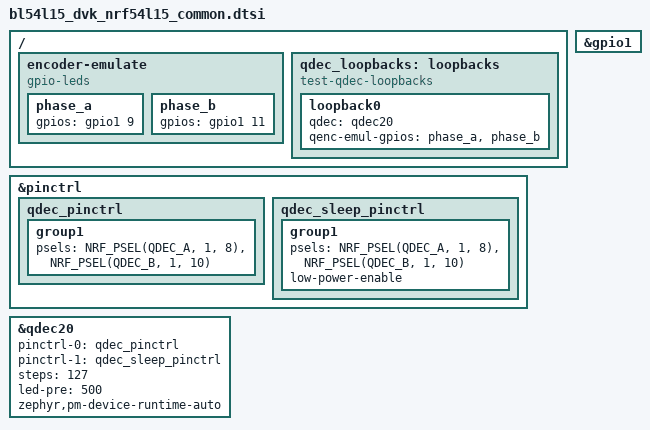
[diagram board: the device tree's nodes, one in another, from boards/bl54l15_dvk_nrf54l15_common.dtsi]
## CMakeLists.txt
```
# SPDX-License-Identifier: Apache-2.0

cmake_minimum_required(VERSION 3.28.0)

find_package(Zephyr REQUIRED HINTS $ENV{ZEPHYR_BASE})
project(qdec_sensor)

FILE(GLOB app_sources src/*.c)

target_sources(app PRIVATE ${app_sources})
```

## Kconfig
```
# Copyright (c) 2025 Nordic Semiconductor ASA
# SPDX-License-Identifier: Apache-2.0

config SECOND_QDEC_INSTANCE
	bool "Enable second !DEC instance"

source "Kconfig.zephyr"
```

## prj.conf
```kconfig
CONFIG_ZTEST=y
CONFIG_SENSOR=y
CONFIG_SENSOR_ASYNC_API=y
CONFIG_GPIO=y
CONFIG_RTIO=y
```

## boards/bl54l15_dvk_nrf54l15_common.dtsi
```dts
/*
 * Copyright 2024 Nordic Semiconductor ASA
 * Copyright 2025 Ezurio LLC
 * SPDX-License-Identifier: Apache-2.0
 */

/ {
	encoder-emulate {
		compatible = "gpio-leds";

		phase_a: phase_a {
			gpios = <&gpio1 9 GPIO_ACTIVE_HIGH>;
		};

		phase_b: phase_b {
			gpios = <&gpio1 11 GPIO_ACTIVE_HIGH>;
		};
	};

	qdec_loopbacks: loopbacks {
		compatible = "test-qdec-loopbacks";

		loopback0 {
			qdec = <&qdec20>;
			qenc-emul-gpios = <&phase_a &phase_b>;
		};
	};
};

&pinctrl {
	qdec_pinctrl: qdec_pinctrl {
		group1 {
			psels = <NRF_PSEL(QDEC_A, 1, 8)>,
				<NRF_PSEL(QDEC_B, 1, 10)>;
		};
	};

	qdec_sleep_pinctrl: qdec_sleep_pinctrl {
		group1 {
			psels = <NRF_PSEL(QDEC_A, 1, 8)>,
				<NRF_PSEL(QDEC_B, 1, 10)>;
			low-power-enable;
		};
	};
};

&gpio1 {
	status = "okay";
};

&qdec20 {
	pinctrl-0 = <&qdec_pinctrl>;
	pinctrl-1 = <&qdec_sleep_pinctrl>;
	pinctrl-names = "default", "sleep";
	steps = <127>;
	led-pre = <500>;
	zephyr,pm-device-runtime-auto;
	status = "okay";
};
```

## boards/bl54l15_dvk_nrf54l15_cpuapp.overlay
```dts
/*
 * Copyright 2024 Nordic Semiconductor ASA
 * Copyright 2025 Ezurio LLC
 * SPDX-License-Identifier: Apache-2.0
 */

#include "bl54l15_dvk_nrf54l15_common.dtsi"

/* To prevent enabling console receiver. */
&uart20 {
	disable-rx;
};
```

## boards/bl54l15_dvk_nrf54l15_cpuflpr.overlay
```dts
/*
 * Copyright 2024 Nordic Semiconductor ASA
 * Copyright 2025 Ezurio LLC
 * SPDX-License-Identifier: Apache-2.0
 */

#include "bl54l15_dvk_nrf54l15_common.dtsi"

/* To prevent enabling console receiver. */
&uart30 {
	disable-rx;
};
```

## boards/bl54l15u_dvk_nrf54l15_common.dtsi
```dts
/*
 * Copyright 2024 Nordic Semiconductor ASA
 * Copyright 2025 Ezurio LLC
 * SPDX-License-Identifier: Apache-2.0
 */

/ {
	encoder-emulate {
		compatible = "gpio-leds";

		phase_a: phase_a {
			gpios = <&gpio1 9 GPIO_ACTIVE_HIGH>;
		};

		phase_b: phase_b {
			gpios = <&gpio1 11 GPIO_ACTIVE_HIGH>;
		};
	};

	qdec_loopbacks: loopbacks {
		compatible = "test-qdec-loopbacks";

		loopback0 {
			qdec = <&qdec20>;
			qenc-emul-gpios = <&phase_a &phase_b>;
		};
	};
};

&pinctrl {
	qdec_pinctrl: qdec_pinctrl {
		group1 {
			psels = <NRF_PSEL(QDEC_A, 1, 8)>,
				<NRF_PSEL(QDEC_B, 1, 10)>;
		};
	};

	qdec_sleep_pinctrl: qdec_sleep_pinctrl {
		group1 {
			psels = <NRF_PSEL(QDEC_A, 1, 8)>,
				<NRF_PSEL(QDEC_B, 1, 10)>;
			low-power-enable;
		};
	};
};

&gpio1 {
	status = "okay";
};

&qdec20 {
	status = "okay";
	pinctrl-0 = <&qdec_pinctrl>;
	pinctrl-1 = <&qdec_sleep_pinctrl>;
	pinctrl-names = "default", "sleep";
	steps = <127>;
	led-pre = <500>;
	zephyr,pm-device-runtime-auto;
};
```

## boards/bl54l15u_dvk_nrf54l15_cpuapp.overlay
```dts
/*
 * Copyright 2024 Nordic Semiconductor ASA
 * Copyright 2025 Ezurio LLC
 * SPDX-License-Identifier: Apache-2.0
 */

#include "bl54l15u_dvk_nrf54l15_common.dtsi"

/* To prevent enabling console receiver. */
&uart20 {
	disable-rx;
};
```

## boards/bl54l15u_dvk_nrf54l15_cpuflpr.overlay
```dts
/*
 * Copyright 2024 Nordic Semiconductor ASA
 * Copyright 2025 Ezurio LLC
 * SPDX-License-Identifier: Apache-2.0
 */

#include "bl54l15u_dvk_nrf54l15_common.dtsi"

/* To prevent enabling console receiver. */
&uart30 {
	disable-rx;
};
```

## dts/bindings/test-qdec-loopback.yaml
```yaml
description: |
  Binding describing loopbacks required to run tests/boards/nrf/qdec test in Zephyr.

compatible: "test-qdec-loopbacks"

child-binding:
  description: |
    Binding describing a single loopback pair consisting of a QDEC device and two "gpio-leds" pins
    working as a quadrature encoder for the test.
  properties:
    qdec:
      type: phandle
      required: true
      description: Node of the QDEC device used to capture quadrature signal in the loopback.
    qenc-emul-gpios:
      type: phandles
      required: true
      description: |
        Children nodes of "gpio-leds" compatible used to generate quadrature signal. The first
        phandles outputs phase A signal, the second one outputs phase B signal.
```

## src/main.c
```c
/*
 * Copyright (c) 2024, Nordic Semiconductor ASA
 *
 * SPDX-License-Identifier: Apache-2.0
 */

#include <zephyr/ztest.h>
#include <zephyr/kernel.h>
#include <zephyr/device.h>
#include <zephyr/drivers/sensor.h>
#include <zephyr/drivers/gpio.h>
#include <zephyr/pm/device_runtime.h>
#include <zephyr/rtio/rtio.h>

/**
 * Structure grouping gpio pins used for QENC emulation connected with a QDEC device
 * with a loopback.
 */
struct qdec_qenc_loopback {
	struct gpio_dt_spec qenc_phase_a;
	struct gpio_dt_spec qenc_phase_b;

	const struct device *qdec;
	uint32_t qdec_config_step;

	struct rtio_iodev *qdec_iodev;
};

static K_SEM_DEFINE(sem, 0, 1);

RTIO_DEFINE(ctx, 1, 1);

#define GET_QDEC_QENC_IODEV_DEFINE(x)                                                              \
	SENSOR_DT_READ_IODEV(iodev##x, DT_PHANDLE(x, qdec), {SENSOR_CHAN_ROTATION, 0});

DT_FOREACH_CHILD(DT_NODELABEL(qdec_loopbacks), GET_QDEC_QENC_IODEV_DEFINE)

#define GET_QDEC_QENC_LOOPBACK(x)                                                                  \
	{                                                                                          \
		.qenc_phase_a = GPIO_DT_SPEC_GET(DT_PHANDLE_BY_IDX(x, qenc_emul_gpios, 0), gpios), \
		.qenc_phase_b = GPIO_DT_SPEC_GET(DT_PHANDLE_BY_IDX(x, qenc_emul_gpios, 1), gpios), \
		.qdec = DEVICE_DT_GET(DT_PHANDLE(x, qdec)),                                        \
		.qdec_config_step = DT_PROP_BY_PHANDLE(x, qdec, steps),                            \
		.qdec_iodev = &iodev##x,                                                           \
	}

struct qdec_qenc_loopback loopbacks[] = {
	DT_FOREACH_CHILD_SEP(DT_NODELABEL(qdec_loopbacks), GET_QDEC_QENC_LOOPBACK, (,))
};

#define TESTED_QDEC_COUNT ARRAY_SIZE(loopbacks)

static struct sensor_trigger qdec_trigger = {.type = SENSOR_TRIG_DATA_READY,
					     .chan = SENSOR_CHAN_ROTATION};

static bool toggle_a = true;
static struct qdec_qenc_loopback *loopback_currently_under_test;

static void qdec_trigger_handler(const struct device *dev, const struct sensor_trigger *trigger)
{
	zassert_not_null(dev);
	zassert_not_null(trigger);
	/* trigger should be stored as a pointer in a driver
	 * thus this address should match
	 */
	zassert_equal_ptr(trigger, &qdec_trigger);

	k_sem_give(&sem);
}

static void qenc_emulate_work_handler(struct k_work *work)
{
	/* Check if emulation has been stopped after submitting this work item. */
	if (loopback_currently_under_test == NULL) {
		return;
	}

	if (toggle_a) {
		gpio_pin_toggle_dt(&loopback_currently_under_test->qenc_phase_a);
	} else {
		gpio_pin_toggle_dt(&loopback_currently_under_test->qenc_phase_b);
	}
	toggle_a = !toggle_a;
}

static K_WORK_DEFINE(qenc_emulate_work, qenc_emulate_work_handler);

static void qenc_emulate_timer_handler(struct k_timer *dummy)
{
	k_work_submit(&qenc_emulate_work);
}

static K_TIMER_DEFINE(qenc_emulate_timer, qenc_emulate_timer_handler, NULL);

static void qenc_emulate_reset_pin(const struct gpio_dt_spec *gpio_dt)
{
	int rc;

	rc = gpio_pin_set_dt(gpio_dt, 0);
	zassert_ok(rc, "%s: pin set failed: %d", gpio_dt->port->name, rc);
}

static void qenc_emulate_setup_pin(const struct gpio_dt_spec *gpio_dt)
{
	int rc;

	rc = gpio_is_ready_dt(gpio_dt);
	zassert_true(rc, "%s: device not ready: %d", gpio_dt->port->name, rc);

	rc = gpio_pin_configure_dt(gpio_dt, GPIO_OUTPUT);
	zassert_true(rc == 0, "%s: pin configure failed: %d", gpio_dt->port->name, rc);
}

static void qenc_emulate_start(struct qdec_qenc_loopback *loopback, k_timeout_t period,
		bool forward)
{
	qenc_emulate_reset_pin(&loopback->qenc_phase_a);
	qenc_emulate_reset_pin(&loopback->qenc_phase_b);

	toggle_a = !forward;
	loopback_currently_under_test = loopback;
	k_timer_start(&qenc_emulate_timer, period, period);
}

static void qenc_emulate_stop(void)
{
	if (loopback_currently_under_test) {
		k_timer_stop(&qenc_emulate_timer);
		qenc_emulate_reset_pin(&loopback_currently_under_test->qenc_phase_a);
		qenc_emulate_reset_pin(&loopback_currently_under_test->qenc_phase_b);

		loopback_currently_under_test = NULL;
	}
}

static void qenc_emulate_verify_reading(struct qdec_qenc_loopback *loopback,
		int emulator_period_ms, int emulation_duration_ms, bool forward,
		bool overflow_expected)
{
	int rc;
	struct sensor_value val = {0};
	int32_t expected_steps = emulation_duration_ms / emulator_period_ms;
	int32_t expected_reading = 360 * expected_steps / loopback->qdec_config_step;
	int32_t delta = expected_reading / 4;

	if (!forward) {
		expected_reading *= -1;
	}

	qenc_emulate_start(loopback, K_MSEC(emulator_period_ms), forward);

	/* wait for some readings */
	k_msleep(emulation_duration_ms);

	rc = sensor_sample_fetch(loopback->qdec);

	if (!overflow_expected) {
		zassert_true(rc == 0, "Failed to fetch sample (%d)", rc);
	} else {
		zassert_true(rc == -EOVERFLOW, "Failed to detect overflow");
	}

	rc = sensor_channel_get(loopback->qdec, SENSOR_CHAN_ROTATION, &val);
	zassert_true(rc == 0, "Failed to get sample (%d)", rc);

	TC_PRINT("Expected reading: %d, actual value: %d, delta: %d\n",
			expected_reading, val.val1, delta);
	if (!overflow_expected) {
		zassert_within(val.val1, expected_reading, delta,
			       "Expected reading: %d,  but got: %d", expected_reading, val.val1);
	}

	qenc_emulate_stop();

	/* wait and get readings to clear state */
	k_msleep(100);

	rc = sensor_sample_fetch(loopback->qdec);
	zassert_true(rc == 0, "Failed to fetch sample (%d)", rc);

	rc = sensor_channel_get(loopback->qdec, SENSOR_CHAN_ROTATION, &val);
	zassert_true(rc == 0, "Failed to get sample (%d)", rc);
}

static void sensor_trigger_set_and_disable(struct qdec_qenc_loopback *loopback)
{
	int rc;

	if (IS_ENABLED(CONFIG_PM_DEVICE_RUNTIME)) {
		pm_device_runtime_get(loopback->qdec);
	}

	k_sem_give(&sem);

	qdec_trigger.type = SENSOR_TRIG_DATA_READY;
	qdec_trigger.chan = SENSOR_CHAN_ALL;
	rc = sensor_trigger_set(loopback->qdec, &qdec_trigger, qdec_trigger_handler);
	zassume_true(rc != -ENOSYS, "sensor_trigger_set not supported");

	zassert_true(rc == 0, "sensor_trigger_set failed: %d", rc);

	qenc_emulate_start(loopback, K_MSEC(10), true);

	/* emulation working, handler should be called */
	rc = k_sem_take(&sem, K_MSEC(200));
	zassert_true(rc == 0, "qdec handler should be triggered (%d)", rc);

	qenc_emulate_stop();

	/* emulation not working, but there maybe old trigger, ignore */
	rc = k_sem_take(&sem, K_MSEC(200));

	if (IS_ENABLED(CONFIG_PM_DEVICE_RUNTIME)) {
		pm_device_runtime_put(loopback->qdec);
	}

	/* there should be no triggers now*/
	rc = k_sem_take(&sem, K_MSEC(200));
	zassert_true(rc == -EAGAIN, "qdec handler should not be triggered (%d)", rc);

	if (IS_ENABLED(CONFIG_PM_DEVICE_RUNTIME)) {
		pm_device_runtime_get(loopback->qdec);
	}

	/* register empty trigger - disable trigger */
	rc = sensor_trigger_set(loopback->qdec, &qdec_trigger, NULL);
	zassert_true(rc == 0, "sensor_trigger_set failed: %d", rc);

	qenc_emulate_start(loopback, K_MSEC(10), true);

	/* emulation working, but handler not set, thus should not be called */
	rc = k_sem_take(&sem, K_MSEC(200));
	zassert_true(rc == -EAGAIN, "qdec handler should not be triggered (%d)", rc);

	if (IS_ENABLED(CONFIG_PM_DEVICE_RUNTIME)) {
		pm_device_runtime_put(loopback->qdec);
	}

	qenc_emulate_stop();
	k_sem_reset(&sem);
}

/**
 * @brief sensor_trigger_set test disable trigger
 *
 * Confirm trigger happens after set and stops after being disabled
 *
 */
ZTEST(qdec_sensor, test_sensor_trigger_set_and_disable)
{
	for (size_t i = 0; i < TESTED_QDEC_COUNT; i++) {
		TC_PRINT("Testing QDEC index %d, address: %p\n", i, loopbacks[i].qdec);
		sensor_trigger_set_and_disable(&loopbacks[i]);
	}
}

static void sensor_trigger_set_test(struct qdec_qenc_loopback *loopback)
{
	int rc;
	struct sensor_value val = {0};

	if (IS_ENABLED(CONFIG_PM_DEVICE_RUNTIME)) {
		pm_device_runtime_get(loopback->qdec);
	}

	qdec_trigger.type = SENSOR_TRIG_DATA_READY;
	qdec_trigger.chan = SENSOR_CHAN_ROTATION;
	rc = sensor_trigger_set(loopback->qdec, &qdec_trigger, qdec_trigger_handler);
	zassume_true(rc != -ENOSYS, "sensor_trigger_set not supported");

	zassert_true(rc == 0, "sensor_trigger_set failed: %d", rc);

	qenc_emulate_start(loopback, K_MSEC(10), true);

	/* emulation working now */
	rc = k_sem_take(&sem, K_MSEC(200));
	zassert_true(rc == 0, "qdec handler should be triggered (%d)", rc);

	rc = sensor_sample_fetch(loopback->qdec);
	zassert_true(rc == 0, "Failed to fetch sample (%d)", rc);

	rc = sensor_channel_get(loopback->qdec, SENSOR_CHAN_ROTATION, &val);
	zassert_true(rc == 0, "Failed to fetch sample (%d)", rc);

	TC_PRINT("QDEC reading: %d\n", val.val1);
	zassert_true(val.val1 != 0, "No readings from QDEC");

	if (IS_ENABLED(CONFIG_PM_DEVICE_RUNTIME)) {
		pm_device_runtime_put(loopback->qdec);
	}

	qenc_emulate_stop();
	k_sem_reset(&sem);
}

/**
 * @brief sensor_trigger_set test
 *
 * Confirm trigger happens after set
 *
 */
ZTEST(qdec_sensor, test_sensor_trigger_set)
{
	for (size_t i = 0; i < TESTED_QDEC_COUNT; i++) {
		TC_PRINT("Testing QDEC index %d, address: %p\n", i, loopbacks[i].qdec);
		sensor_trigger_set_test(&loopbacks[i]);
	}
}

static void sensor_trigger_set_negative(struct qdec_qenc_loopback *loopback)
{
	int rc;

	if (IS_ENABLED(CONFIG_PM_DEVICE_RUNTIME)) {
		pm_device_runtime_get(loopback->qdec);
	}

	rc = sensor_trigger_set(loopback->qdec, &qdec_trigger, qdec_trigger_handler);
	zassume_true(rc != -ENOSYS, "sensor_trigger_set not supported");

	qdec_trigger.type = SENSOR_TRIG_MAX;
	qdec_trigger.chan = SENSOR_CHAN_ROTATION;

	rc = sensor_trigger_set(loopback->qdec, &qdec_trigger, qdec_trigger_handler);
	zassume_true(rc < 0, "sensor_trigger_set should fail due to invalid trigger type");

	qdec_trigger.type = SENSOR_TRIG_DATA_READY;
	qdec_trigger.chan = SENSOR_CHAN_MAX;

	rc = sensor_trigger_set(loopback->qdec, &qdec_trigger, qdec_trigger_handler);
	zassume_true(rc < 0, "sensor_trigger_set should fail due to invalid channel");

	if (IS_ENABLED(CONFIG_PM_DEVICE_RUNTIME)) {
		pm_device_runtime_put(loopback->qdec);
	}
}

/**
 * @brief sensor_trigger_set test negative
 *
 * Confirm setting trigger with invalid data does not work
 *
 */
ZTEST(qdec_sensor, test_sensor_trigger_set_negative)
{
	for (size_t i = 0; i < TESTED_QDEC_COUNT; i++) {
		TC_PRINT("Testing QDEC index %d, address: %p\n", i, loopbacks[i].qdec);
		sensor_trigger_set_negative(&loopbacks[i]);
	}
}

/**
 * @brief QDEC readings tests
 *
 * Valid reading from QDEC base on simulated signal
 *
 */
ZTEST(qdec_sensor, test_qdec_readings)
{
	for (size_t i = 0; i < TESTED_QDEC_COUNT; i++) {
		if (IS_ENABLED(CONFIG_PM_DEVICE_RUNTIME)) {
			pm_device_runtime_get(loopbacks[i].qdec);
		}

		TC_PRINT("Testing QDEC index %d, address: %p\n", i, loopbacks[i].qdec);
		qenc_emulate_verify_reading(&loopbacks[i], 10,  100,  true, false);
		qenc_emulate_verify_reading(&loopbacks[i],  2,  500,  true, false);
		qenc_emulate_verify_reading(&loopbacks[i], 10,  200, false, false);
		qenc_emulate_verify_reading(&loopbacks[i],  1, 1000, false,  true);
		qenc_emulate_verify_reading(&loopbacks[i],  1, 1000,  true,  true);

		if (IS_ENABLED(CONFIG_PM_DEVICE_RUNTIME)) {
			pm_device_runtime_put(loopbacks[i].qdec);
		}
	}
}

static void sensor_channel_get_empty(const struct device *const dev)
{
	int rc;
	struct sensor_value val = {0};

	if (IS_ENABLED(CONFIG_PM_DEVICE_RUNTIME)) {
		pm_device_runtime_get(dev);
	}

	/* wait for potential new readings */
	k_msleep(100);

	rc = sensor_sample_fetch(dev);
	zassert_true(rc == 0, "Failed to fetch sample (%d)", rc);

	/* get readings but ignore them, as they may include reading from time
	 * when emulation was still working (i.e. during previous test)
	 */
	rc = sensor_channel_get(dev, SENSOR_CHAN_ROTATION, &val);
	zassert_true(rc == 0, "Failed to get sample (%d)", rc);

	/* wait for potential new readings */
	k_msleep(100);

	rc = sensor_sample_fetch(dev);
	zassert_true(rc == 0, "Failed to fetch sample (%d)", rc);

	/* emulation was not working, expect no readings */
	rc = sensor_channel_get(dev, SENSOR_CHAN_ROTATION, &val);
	zassert_true(rc == 0, "Failed to get sample (%d)", rc);
	zassert_true(val.val1 == 0, "Expected no readings but got: %d", val.val1);
	zassert_true(val.val2 == 0, "Expected no readings but got: %d", val.val2);

	if (IS_ENABLED(CONFIG_PM_DEVICE_RUNTIME)) {
		pm_device_runtime_put(dev);
	}
}

/**
 * @brief sensor_channel_get test with no emulation
 *
 * Confirm getting empty reading from QDEC
 *
 */
ZTEST(qdec_sensor, test_sensor_channel_get_empty)
{
	for (size_t i = 0; i < TESTED_QDEC_COUNT; i++) {
		TC_PRINT("Testing QDEC index %d, address: %p\n", i, loopbacks[i].qdec);
		sensor_channel_get_empty(loopbacks[i].qdec);
	}
}

static void sensor_channel_get_test(struct qdec_qenc_loopback *loopback)
{
	int rc;
	struct sensor_value val_first = {0};
	struct sensor_value val_second = {0};

	if (IS_ENABLED(CONFIG_PM_DEVICE_RUNTIME)) {
		pm_device_runtime_get(loopback->qdec);
	}

	qenc_emulate_start(loopback, K_MSEC(10), true);

	/* wait for some readings*/
	k_msleep(100);

	rc = sensor_sample_fetch(loopback->qdec);
	zassert_true(rc == 0, "Failed to fetch sample (%d)", rc);

	rc = sensor_channel_get(loopback->qdec, SENSOR_CHAN_ROTATION, &val_first);
	zassert_true(rc == 0, "Failed to get sample (%d)", rc);
	zassert_true(val_first.val1 != 0, "No readings from QDEC");

	/* wait for more readings*/
	k_msleep(200);

	rc = sensor_channel_get(loopback->qdec, SENSOR_CHAN_ROTATION, &val_second);
	zassert_true(rc == 0, "Failed to fetch sample (%d)", rc);
	zassert_true(val_second.val1 != 0, "No readings from QDEC");

	/* subsequent calls of sensor_channel_get without calling sensor_sample_fetch
	 * should yield the same value
	 */
	zassert_true(val_first.val1 == val_second.val1,
		     "Expected the same readings: %d vs %d",
		     val_first.val1,
		     val_second.val1);

	zassert_true(val_first.val2 == val_second.val2,
		     "Expected the same readings: %d vs %d",
		     val_first.val2,
		     val_second.val2);

	if (IS_ENABLED(CONFIG_PM_DEVICE_RUNTIME)) {
		pm_device_runtime_put(loopback->qdec);
	}
}

/**
 * @brief sensor_channel_get test with emulation
 *
 * Confirm getting readings from QDEC
 *
 */
ZTEST(qdec_sensor, test_sensor_channel_get)
{
	for (size_t i = 0; i < TESTED_QDEC_COUNT; i++) {
		TC_PRINT("Testing QDEC index %d, address: %p\n", i, loopbacks[i].qdec);
		sensor_channel_get_test(&loopbacks[i]);
	}
}

static void sensor_channel_get_negative(struct qdec_qenc_loopback *loopback)
{
	int rc;
	struct sensor_value val = {0};

	if (IS_ENABLED(CONFIG_PM_DEVICE_RUNTIME)) {
		pm_device_runtime_get(loopback->qdec);
	}

	qenc_emulate_start(loopback, K_MSEC(10), true);

	/* wait for some readings*/
	k_msleep(100);

	rc = sensor_sample_fetch(loopback->qdec);
	zassert_true(rc == 0, "Failed to fetch sample (%d)", rc);

	rc = sensor_channel_get(loopback->qdec, SENSOR_CHAN_MAX, &val);
	zassert_true(rc < 0, "Should failed to get sample (%d)", rc);
	zassert_true(val.val1 == 0, "Some readings from QDEC: %d", val.val1);
	zassert_true(val.val2 == 0, "Some readings from QDEC: %d", val.val2);

	if (IS_ENABLED(CONFIG_PM_DEVICE_RUNTIME)) {
		pm_device_runtime_put(loopback->qdec);
	}
}

/**
 * @brief sensor_channel_get test negative
 *
 * Confirm getting readings from QDEC with invalid channel
 *
 */
ZTEST(qdec_sensor, test_sensor_channel_get_negative)
{
	for (size_t i = 0; i < TESTED_QDEC_COUNT; i++) {
		TC_PRINT("Testing QDEC index %d, address: %p\n", i, loopbacks[i].qdec);
		sensor_channel_get_negative(&loopbacks[i]);
	}
}

static void sensor_sample_fetch_test(const struct device *const dev)
{
	int rc;

	if (IS_ENABLED(CONFIG_PM_DEVICE_RUNTIME)) {
		pm_device_runtime_get(dev);
	}

	rc = sensor_sample_fetch(dev);
	zassert_true(rc == 0, "Failed to fetch sample (%d)", rc);

	rc = sensor_sample_fetch_chan(dev, SENSOR_CHAN_ROTATION);
	zassert_true(rc == 0, "Failed to fetch sample (%d)", rc);

	rc = sensor_sample_fetch_chan(dev, SENSOR_CHAN_MAX);
	zassert_true(rc < 0, "Should fail to fetch sample from invalid channel (%d)", rc);

	if (IS_ENABLED(CONFIG_PM_DEVICE_RUNTIME)) {
		pm_device_runtime_put(dev);
	}
}

/**
 * @brief sensor_sample_fetch(_chan) test
 *
 * Confirm fetching work with QDEC specific channel - rotation
 *
 */
ZTEST(qdec_sensor, test_sensor_sample_fetch)
{
	for (size_t i = 0; i < TESTED_QDEC_COUNT; i++) {
		TC_PRINT("Testing QDEC index %d, address: %p\n", i, loopbacks[i].qdec);
		sensor_sample_fetch_test(loopbacks[i].qdec);
	}
}

static void sensor_read_and_decode_test(struct qdec_qenc_loopback *loopback)
{
	int rc;
	int num_frames_decoded;
	uint8_t buf[128];
	uint32_t temp_fit = 0;
	struct sensor_q31_data data = {0};
	q31_t rot_deg;
	const struct sensor_decoder_api *decoder;

	if (IS_ENABLED(CONFIG_PM_DEVICE_RUNTIME)) {
		pm_device_runtime_get(loopback->qdec);
	}

	qenc_emulate_start(loopback, K_MSEC(10), true);

	/* wait for some readings*/
	k_msleep(100);

	rc = sensor_read(loopback->qdec_iodev, &ctx, buf, 128);
	zassert_true(rc == 0, "Failed to read sample (%d)", rc);

	rc = sensor_get_decoder(loopback->qdec, &decoder);
	zassert_true(rc == 0, "Failed to get sensor decoder (%d)", rc);

	num_frames_decoded = decoder->decode(
		buf, (struct sensor_chan_spec){SENSOR_CHAN_ROTATION, 0}, &temp_fit, 1, &data);
	zassert_equal(num_frames_decoded, 1, "Failed sensor decode operation (%d)",
		      num_frames_decoded);

	rot_deg = data.readings[0].value;
	zassert_true(rot_deg != 0, "No readings from QDEC");

	if (IS_ENABLED(CONFIG_PM_DEVICE_RUNTIME)) {
		pm_device_runtime_put(loopback->qdec);
	}

	qenc_emulate_stop();
}

/**
 * @brief sensor_read and decode test
 *
 * Confirm getting readings from QDEC with RTIO read and decode implementation
 *
 */
ZTEST(qdec_sensor, test_sensor_read_and_decode)
{
	for (size_t i = 0; i < TESTED_QDEC_COUNT; i++) {
		TC_PRINT("Testing QDEC index %d, address: %p\n", i, loopbacks[i].qdec);
		sensor_read_and_decode_test(&loopbacks[i]);
	}
}

static void *setup(void)
{
	for (size_t i = 0; i < TESTED_QDEC_COUNT; i++) {
		int rc = device_is_ready(loopbacks[i].qdec);

		zassert_true(rc, "QDEC index %d not ready: %d", i, rc);

		qenc_emulate_setup_pin(&loopbacks[i].qenc_phase_a);
		qenc_emulate_setup_pin(&loopbacks[i].qenc_phase_b);
	}
	return NULL;
}

static void before(void *fixture)
{
	ARG_UNUSED(fixture);

	qenc_emulate_stop();
}

static void after(void *fixture)
{
	ARG_UNUSED(fixture);

	qenc_emulate_stop();
	k_sem_reset(&sem);
}

ZTEST_SUITE(qdec_sensor, NULL, setup, before, after, NULL);
```
